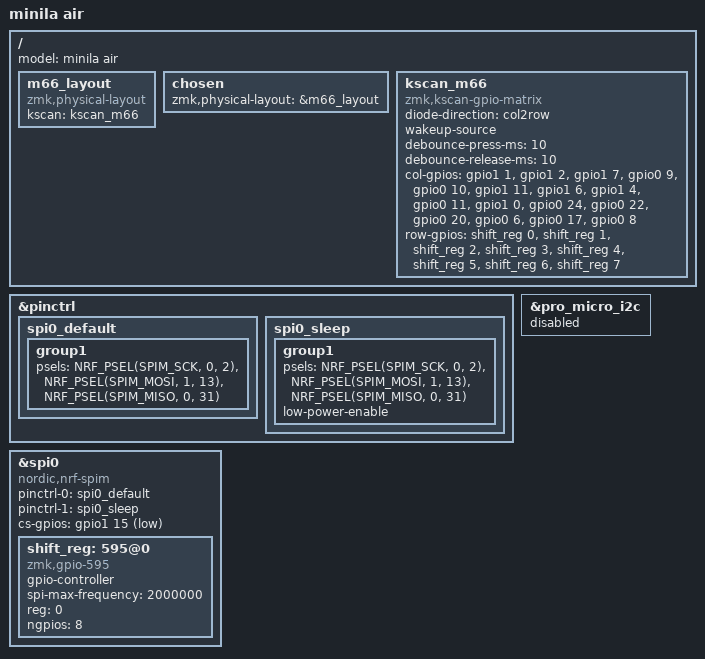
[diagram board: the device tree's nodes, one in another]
#include "mlego_m66_rev4_layout.dtsi"

/ {
   model = "minila air";

   m66_layout: m66_layout {
        compatible = "zmk,physical-layout";
        kscan = <&kscan_m66>;
   };

   chosen {
     zmk,physical-layout = &m66_layout;
   };

   kscan_m66: kscan_m66 {
     compatible = "zmk,kscan-gpio-matrix";
     diode-direction = "col2row";
     wakeup-source; 
     debounce-press-ms = <10>;
     debounce-release-ms = <10>;
     col-gpios = 
          <&gpio1 1  (GPIO_ACTIVE_HIGH)>,   /* C0  → P1.01 */
          <&gpio1 2  (GPIO_ACTIVE_HIGH)>,   /* C1  → P1.02 */
          <&gpio1 7  (GPIO_ACTIVE_HIGH)>,   /* C2  → P1.07 */
          <&gpio0 9  (GPIO_ACTIVE_HIGH)>,   /* C3  → P0.09 */
          <&gpio0 10 (GPIO_ACTIVE_HIGH)>,   /* C4  → P0.10 */
          <&gpio1 11 (GPIO_ACTIVE_HIGH)>,   /* C5  → P1.11 */
          <&gpio1 6  (GPIO_ACTIVE_HIGH)>,   /* C6  → P1.06 */
          <&gpio1 4  (GPIO_ACTIVE_HIGH)>,   /* C7  → P1.04 */
          <&gpio0 11 (GPIO_ACTIVE_HIGH)>,   /* C8  → P0.11 */
          <&gpio1 0  (GPIO_ACTIVE_HIGH)>,   /* C9  → P1.00 */
          <&gpio0 24 (GPIO_ACTIVE_HIGH)>,   /* C10 → P0.24 */
          <&gpio0 22 (GPIO_ACTIVE_HIGH)>,   /* C11 → P0.22 */
          <&gpio0 20 (GPIO_ACTIVE_HIGH)>,   /* C12 → P0.20 */
          <&gpio0 6  (GPIO_ACTIVE_HIGH)>,   /* C13 → P0.06 */
          <&gpio0 17 (GPIO_ACTIVE_HIGH)>,   /* C14 → P0.17 */
          <&gpio0 8  (GPIO_ACTIVE_HIGH)>;   /* C15 → P0.08 */
     row-gpios = 
          <&shift_reg 0 (GPIO_ACTIVE_HIGH | GPIO_PULL_DOWN)>,  /* R0 → QA */
          <&shift_reg 1 (GPIO_ACTIVE_HIGH | GPIO_PULL_DOWN)>,  /* R1 → QB */
          <&shift_reg 2 (GPIO_ACTIVE_HIGH | GPIO_PULL_DOWN)>,  /* R2 → QC */
          <&shift_reg 3 (GPIO_ACTIVE_HIGH | GPIO_PULL_DOWN)>,  /* R3 → QD */
          <&shift_reg 4 (GPIO_ACTIVE_HIGH | GPIO_PULL_DOWN)>,  /* R4 → QE */
          <&shift_reg 5 (GPIO_ACTIVE_HIGH | GPIO_PULL_DOWN)>,  /* R5 → QF */
          <&shift_reg 6 (GPIO_ACTIVE_HIGH | GPIO_PULL_DOWN)>,  /* R6 → QG */
          <&shift_reg 7 (GPIO_ACTIVE_HIGH | GPIO_PULL_DOWN)>;  /* R7 → QH */
   };
};

&pinctrl {
    spi0_default: spi0_default {
        group1 {
            psels =   <NRF_PSEL(SPIM_SCK, 0, 2)> 
                    , <NRF_PSEL(SPIM_MOSI, 1, 13)>
                    , <NRF_PSEL(SPIM_MISO, 0, 31)>
                    ;
        };
    };
    spi0_sleep: spi0_sleep {
        group1 {
            psels =   <NRF_PSEL(SPIM_SCK, 0, 2)> 
                    , <NRF_PSEL(SPIM_MOSI, 1, 13)>
                    , <NRF_PSEL(SPIM_MISO, 0, 31)>
                    ;
            low-power-enable;
        };
    };
};

&pro_micro_i2c {
    status = "disabled";
};

board_spi: &spi0 {
  status = "okay";
  compatible = "nordic,nrf-spim";
  pinctrl-0 = <&spi0_default>;
  pinctrl-1 = <&spi0_sleep>;
  pinctrl-names = "default", "sleep";
  cs-gpios = <&gpio1 15 GPIO_ACTIVE_LOW>;  /* RCLK → P1.15 */

  shift_reg: 595@0 {
    compatible = "zmk,gpio-595";
    status = "okay";
    gpio-controller;
    spi-max-frequency = <2000000>;
    #gpio-cells = <2>;
    reg = <0>;
    ngpios = <8>;
  };
};
